# V32F20x_CM33 register map
File version: 1.0.3
CPU: CM33 r0p4, little endian, MPU, FPU, DSP, 3 interrupt priority bits, 8 SAU regions
Registers are 32-bit, read-write, reset 0x0 unless marked. A register's access mark holds for its fields unless they carry their own. Offsets are from the block's base; [hi:lo] are bit positions; {n}, {i} and the like mark numbered series.

## RNG — RNG Peripheral Interface
Base 0x40060000
Same registers: SEC_RNG 0x50060000
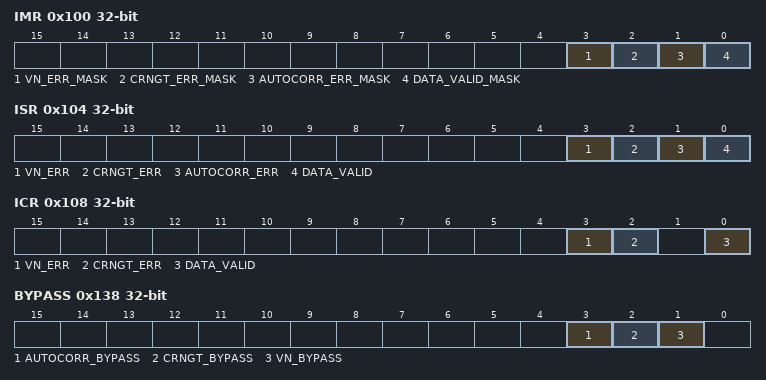
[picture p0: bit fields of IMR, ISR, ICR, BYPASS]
0x100 IMR — RNG interrupt mask register.
  [3] VN_ERR_MASK — This bit masks the VN_ERR interrupt signal from RNG_ISR register
  [2] CRNGT_ERR_MASK — This bit masks the CRNGT_ERR interrupt signal from RNG_ISR register
  [1] AUTOCORR_ERR_MASK — This bit masks the AUTOCORR_ERR interrupt signal from RNG_ISR register
  [0] DATA_VALID_MASK — This bit masks the DATA_VALID interrupt signal from RNG_ISR register
0x104 ISR — RNG interrupt status register.
  [3] VN_ERR — A Von Neumann error occurs if 32 consecutive collected bits are identical that is 32 zeros or 32 ones
  [2] CRNGT_ERR — When set to 1 it indicates a Continuous Random Number Generation Testing CRNGT error in the TRNG test failed
  [1] AUTOCORR_ERR — When set to 1 it indicates that the Autocorrelation test failed four times in a row
  [0] DATA_VALID — Set to 1 when 192 bits have been collected in the RNG and the DATA0 5 registers are ready to be read
0x108 ICR — RNG interrupt clear register.
  [3] VN_ERR — Write 1 to clear a Von Neumann error.
  [2] CRNGT_ERR — Write 1 to clear a Continuous Random Number Generation Testing CRNGT error
  [0] DATA_VALID — Write 1 after DATA0 5 registers have been read to clear DATA_VALID status
0x10C CFG — RNG configure register.
  [1:0] CHAIN_SEL — Selects the length of inverters in the ring oscillator
{0x114+4i} DATA{i} (i=0..5) — RNG data register {i}.
  [31:0] DATA — Returns bits[{32i+31}:{32i}] of entropy holding register.
0x12C CMD — RNG source enable register.
  [0] EN — 1: The entropy source is enabled.
0x130 CNT — RNG sample counter register.
  [31:0] CNT — Sets the number of clock cycles between two consecutive ring oscillator samples
0x138 BYPASS — RNG testing bypass register.
  [3] AUTOCORR_BYPASS — When set to 1 the autocorrelation test in the RNG module is bypassed
  [2] CRNGT_BYPASS — When set to 1 the CRNGT test in the RNG module is bypassed
  [1] VN_BYPASS — When set to 1 the Von Neumann balancer in the RNG module is bypassed including the 32 consecutive bits test

## FlashA_MPC — FlashA_MPC Peripheral Interface
Base 0x40071000
Same registers: FlashB_MPC 0x40072000, SRAM0_MPC 0x40073000, SRAM1_MPC 0x40074000, SRAM2_MPC 0x40075000, SRAM3_MPC 0x40076000, SEC_FlashA_MPC 0x50071000, SEC_FlashB_MPC 0x50072000, SEC_SRAM0_MPC 0x50073000, SEC_SRAM1_MPC 0x50074000, SEC_SRAM2_MPC 0x50075000, SEC_SRAM3_MPC 0x50076000
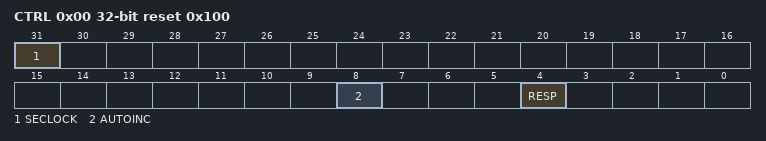
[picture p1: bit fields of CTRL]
0x00 CTRL reset 0x100 — MPC control register.
  [31] SECLOCK — Security lockdown function control.
  [8] AUTOINC — Autoincrement enable control.
  [4] RESP — Security error response configuration.
0x10 BLKMAX ro — Maximum value of block based index register.
0x14 BLKCFG ro — Block configuration register.
  [3:0] SIZE — Block size.
0x18 BLKIDX — Block index register.
  [31:0] IDX — Index value for accessing block based look up table
0x1C BLKLUT — Block lock up table register.
  [31:0] BLKLUT — Block based gating Look Up Table LUT Access to block based look up configuration space pointed to by MPC_BLKIDX
0x20 INTSTS ro — MPC error interrupt status register.
  [0] INTSTS — MPC error interrupt status.
0x24 INTCLR wo — MPC error interrupt clear register.
  [0] INTCLR — MPC error interrupt status clear.

## WDT0 — WDT0 Peripheral Interface
Base 0x40090000
Same registers: WDT1 0x40090800, WDT2 0x41090000, SEC_WDT0 0x50090000, SEC_WDT1 0x50090800
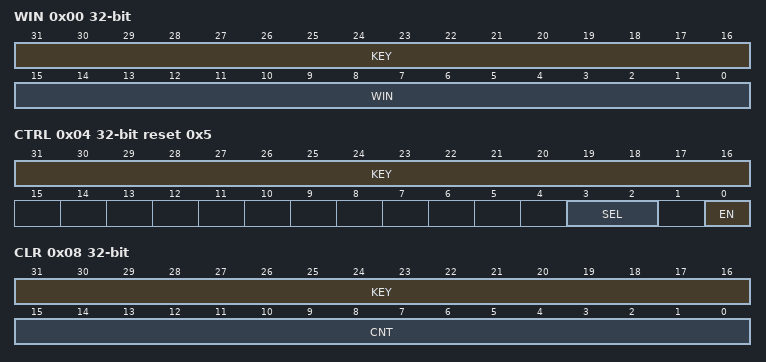
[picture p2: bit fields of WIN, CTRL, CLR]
0x00 WIN — Watchdog window value register.
  [31:16] KEY — Writes to the WDT_WIN register must be accompanied by a write of the value 0xAA55 to this field
  [15:0] WIN — Watch dog window value configuration.
0x04 CTRL reset 0x5 — Watchdog control register.
  [31:16] KEY — Writes to the WDT_CTRL register must be accompanied by a write of the value 0xAA55 to this field
  [3:2] SEL — This register is used to control the WDT counting period
  [0] EN — WDT enable configuration:
0x08 CLR — Watchdog clear register.
  [31:16] KEY — Writes to the WDT_CLR register must be accompanied by a write of the value 0x55AA to this field
  [15:0] CNT — Watchdog counter value.
0x0C STS — Watchdog status register.
  [0] STS
